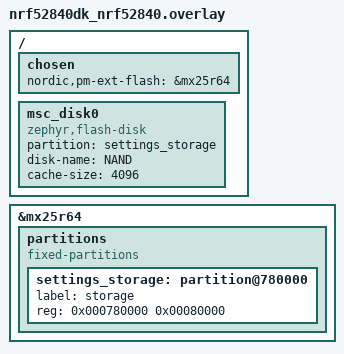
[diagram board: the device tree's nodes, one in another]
/ {
	chosen {
		nordic,pm-ext-flash = &mx25r64;
	};
};

/delete-node/ &storage_partition;

&mx25r64 {
	partitions {
		compatible = "fixed-partitions";
		#address-cells = <1>;
		#size-cells = <1>;

        settings_storage: partition@780000 {
             label = "storage";
             reg = <0x000780000 0x00080000>;
                         
        };
	};
};

/ {
    msc_disk0 {
        compatible = "zephyr,flash-disk";
        partition = <&settings_storage>;
        disk-name = "NAND";
        cache-size = <4096>;
    };
};
